# MSP432E401Y register map
Vendor: Texas Instruments; File version: 3.200
CPU: CM4 r1p2, little endian, no MPU, no FPU, 0x3 interrupt priority bits, 0x0 interrupts
Registers are 32-bit, read-write, no defined reset value unless marked. A register's access mark holds for its fields unless they carry their own. Offsets are from the block's base; [hi:lo] are bit positions; {n}, {i} and the like mark numbered series.

## SSI0 — Register map for SSI0 peripheral
Base 0x40008000; register names take the prefix SSI0
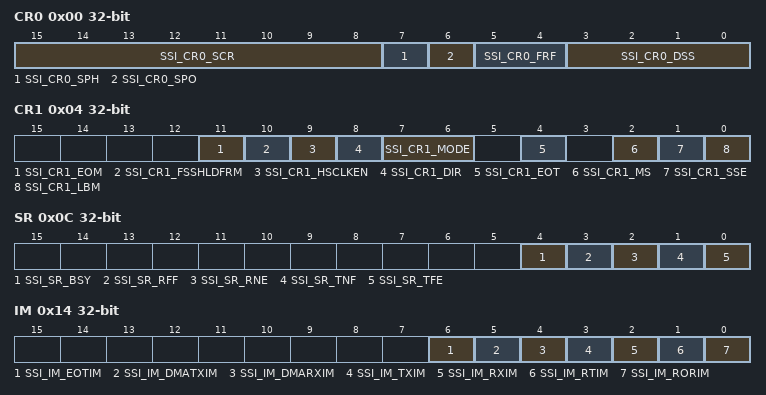
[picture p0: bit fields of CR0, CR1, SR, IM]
0x00 CR0 — SSI Control 0
  [15:8] SSI_CR0_SCR — SSI Serial Clock Rate
  [7] SSI_CR0_SPH — SSI Serial Clock Phase
  [6] SSI_CR0_SPO — SSI Serial Clock Polarity
  [5:4] SSI_CR0_FRF — SSI Frame Format Select
    0=SSI_CR0_FRF_MOTO (Freescale SPI Frame Format); 1=SSI_CR0_FRF_TI (Synchronous Serial Frame Format)
  [3:0] SSI_CR0_DSS — SSI Data Size Select
    {v}={v+1}-bit data (v=3..15)
0x04 CR1 — SSI Control 1
  [11] SSI_CR1_EOM — Stop Frame (End of Message)
  [10] SSI_CR1_FSSHLDFRM — FSS Hold Frame
  [9] SSI_CR1_HSCLKEN — High Speed Clock Enable
  [8] SSI_CR1_DIR — SSI Direction of Operation
  [7:6] SSI_CR1_MODE — SSI Mode
    0=SSI_CR1_MODE_LEGACY (Legacy SSI mode); 1=SSI_CR1_MODE_BI (Bi-SSI mode); 2=SSI_CR1_MODE_QUAD (Quad-SSI Mode); 3=SSI_CR1_MODE_ADVANCED (Advanced SSI Mode with 8-bit packet size)
  [4] SSI_CR1_EOT — End of Transmission
  [2] SSI_CR1_MS — SSI Master/Slave Select
  [1] SSI_CR1_SSE — SSI Synchronous Serial Port Enable
  [0] SSI_CR1_LBM — SSI Loopback Mode
0x08 DR — SSI Data
  [15:0] SSI_DR_DATA — SSI Receive/Transmit Data
0x0C SR — SSI Status
  [4] SSI_SR_BSY — SSI Busy Bit
  [3] SSI_SR_RFF — SSI Receive FIFO Full
  [2] SSI_SR_RNE — SSI Receive FIFO Not Empty
  [1] SSI_SR_TNF — SSI Transmit FIFO Not Full
  [0] SSI_SR_TFE — SSI Transmit FIFO Empty
0x10 CPSR — SSI Clock Prescale
  [7:0] SSI_CPSR_CPSDVSR — SSI Clock Prescale Divisor
0x14 IM — SSI Interrupt Mask
  [6] SSI_IM_EOTIM — End of Transmit Interrupt Mask
  [5] SSI_IM_DMATXIM — SSI Transmit DMA Interrupt Mask
  [4] SSI_IM_DMARXIM — SSI Receive DMA Interrupt Mask
  [3] SSI_IM_TXIM — SSI Transmit FIFO Interrupt Mask
  [2] SSI_IM_RXIM — SSI Receive FIFO Interrupt Mask
  [1] SSI_IM_RTIM — SSI Receive Time-Out Interrupt Mask
  [0] SSI_IM_RORIM — SSI Receive Overrun Interrupt Mask
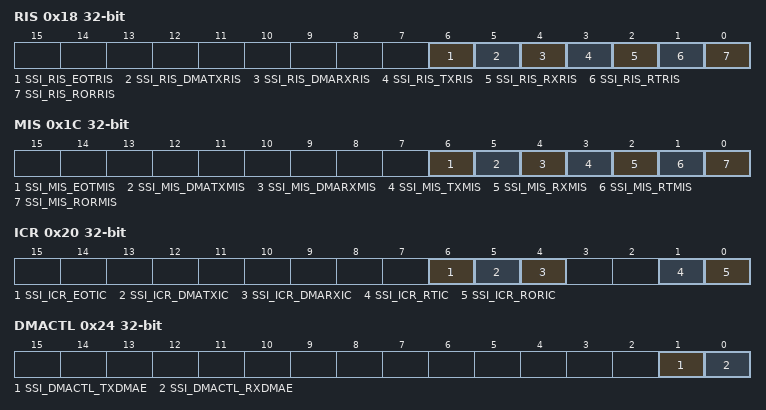
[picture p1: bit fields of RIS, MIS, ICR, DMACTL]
0x18 RIS — SSI Raw Interrupt Status
  [6] SSI_RIS_EOTRIS — End of Transmit Raw Interrupt Status
  [5] SSI_RIS_DMATXRIS — SSI Transmit DMA Raw Interrupt Status
  [4] SSI_RIS_DMARXRIS — SSI Receive DMA Raw Interrupt Status
  [3] SSI_RIS_TXRIS — SSI Transmit FIFO Raw Interrupt Status
  [2] SSI_RIS_RXRIS — SSI Receive FIFO Raw Interrupt Status
  [1] SSI_RIS_RTRIS — SSI Receive Time-Out Raw Interrupt Status
  [0] SSI_RIS_RORRIS — SSI Receive Overrun Raw Interrupt Status
0x1C MIS — SSI Masked Interrupt Status
  [6] SSI_MIS_EOTMIS — End of Transmit Masked Interrupt Status
  [5] SSI_MIS_DMATXMIS — SSI Transmit DMA Masked Interrupt Status
  [4] SSI_MIS_DMARXMIS — SSI Receive DMA Masked Interrupt Status
  [3] SSI_MIS_TXMIS — SSI Transmit FIFO Masked Interrupt Status
  [2] SSI_MIS_RXMIS — SSI Receive FIFO Masked Interrupt Status
  [1] SSI_MIS_RTMIS — SSI Receive Time-Out Masked Interrupt Status
  [0] SSI_MIS_RORMIS — SSI Receive Overrun Masked Interrupt Status
0x20 ICR wo — SSI Interrupt Clear
  [6] SSI_ICR_EOTIC — End of Transmit Interrupt Clear
  [5] SSI_ICR_DMATXIC — SSI Transmit DMA Interrupt Clear
  [4] SSI_ICR_DMARXIC — SSI Receive DMA Interrupt Clear
  [1] SSI_ICR_RTIC — SSI Receive Time-Out Interrupt Clear
  [0] SSI_ICR_RORIC — SSI Receive Overrun Interrupt Clear
0x24 DMACTL — SSI DMA Control
  [1] SSI_DMACTL_TXDMAE — Transmit DMA Enable
  [0] SSI_DMACTL_RXDMAE — Receive DMA Enable
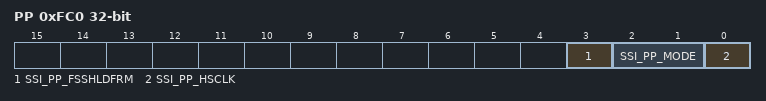
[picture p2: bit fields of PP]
0xFC0 PP — SSI Peripheral Properties
  [3] SSI_PP_FSSHLDFRM — FSS Hold Frame Capability
  [2:1] SSI_PP_MODE — Mode of Operation
    0=SSI_PP_MODE_LEGACY (Legacy SSI mode); 1=SSI_PP_MODE_ADVBI (Legacy mode, Advanced SSI mode and Bi-SSI mode enabled); 2=SSI_PP_MODE_ADVBIQUAD (Legacy mode, Advanced mode, Bi-SSI and Quad-SSI mode enabled)
  [0] SSI_PP_HSCLK — High Speed Capability
0xFC8 CC — SSI Clock Configuration
  [3:0] SSI_CC_CS — SSI Baud Clock Source
    0=SSI_CC_CS_SYSPLL (System clock (based on clock source and divisor factor)); 5=SSI_CC_CS_PIOSC (PIOSC)

## SSI1 — Register map for SSI0 peripheral
Base 0x40009000; register names take the prefix SSI1
Registers as SSI0.

## SSI2 — Register map for SSI0 peripheral
Base 0x4000A000; register names take the prefix SSI2
Registers as SSI0.

## SSI3 — Register map for SSI0 peripheral
Base 0x4000B000; register names take the prefix SSI3
Registers as SSI0.
